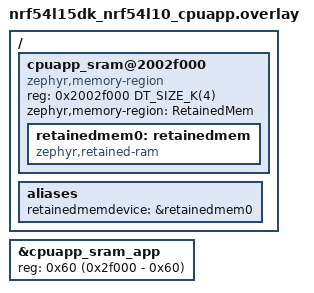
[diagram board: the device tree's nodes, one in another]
/ {
	cpuapp_sram@2002f000 {
		compatible = "zephyr,memory-region", "mmio-sram";
		reg = <0x2002f000 DT_SIZE_K(4)>;
		zephyr,memory-region = "RetainedMem";
		status = "okay";

		retainedmem0: retainedmem {
			compatible = "zephyr,retained-ram";
			status = "okay";
		};
	};

	aliases {
		retainedmemdevice = &retainedmem0;
	};
};

&cpuapp_sram_app {
	/* Shrink SRAM to avoid overlap with retained memory region. The SRAM ends at
	 * 192 - 4 = 188KB = 0x2f000, and starts at 0x60 after the KMU push area, so the
	 * size is that end offset minus 0x60.
	 */
	reg = <0x60 (0x2f000 - 0x60)>;
};
